# STM32F0xx register map
File version: 1.0
Registers are 32-bit, read-write, reset 0x0 unless marked. A register's access mark holds for its fields unless they carry their own. Offsets are from the block's base; [hi:lo] are bit positions; {n}, {i} and the like mark numbered series; 'fields as' and 'values as' point back to an identical list.

## GPIOF — General-purpose I/Os
Base 0x48001400
Same registers: GPIOB 0x48000400, GPIOC 0x48000800, GPIOD 0x48000C00, GPIOE 0x48001000
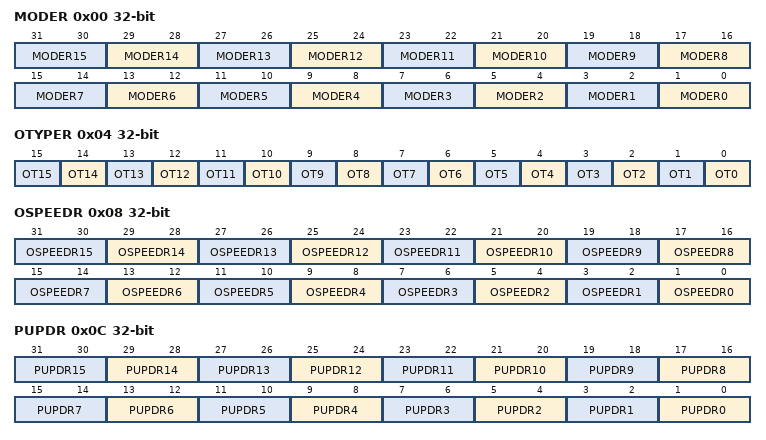
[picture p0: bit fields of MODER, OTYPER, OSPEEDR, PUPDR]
0x00 MODER — GPIO port mode register
  [all] fields
    0=Input mode (Reset); 1=output (General purpose output mode.); 2=Alternate function mode; 3=Analog mode 
  [2n+1:2n] MODER{n} (n=0..15) — Port x configuration bits (y = 0..15)
0x04 OTYPER — GPIO port output type register
  [all] fields
    0=push_pull (Output push-pull (reset state).); 1=open_drain (Output open-drain.)
  [n] OT{n} (n=0..15) — Port x configuration bit {n}
0x08 OSPEEDR — GPIO port output speed register
  [all] fields
    0=low_speed; 1=medium_speed; 2=low_speed_1; 3=high_speed
  [2n+1:2n] OSPEEDR{n} (n=0..15) — Port x configuration bits (y = 0..15)
0x0C PUPDR — GPIO port pull-up/pull-down register
  [all] fields
    0=floating (No Pull-up or Pull-Down.); 1=pull_up (Pull down.); 2=pull_down (Pull up.)
  [2n+1:2n] PUPDR{n} (n=0..15) — Port x configuration bits (y = 0..15)
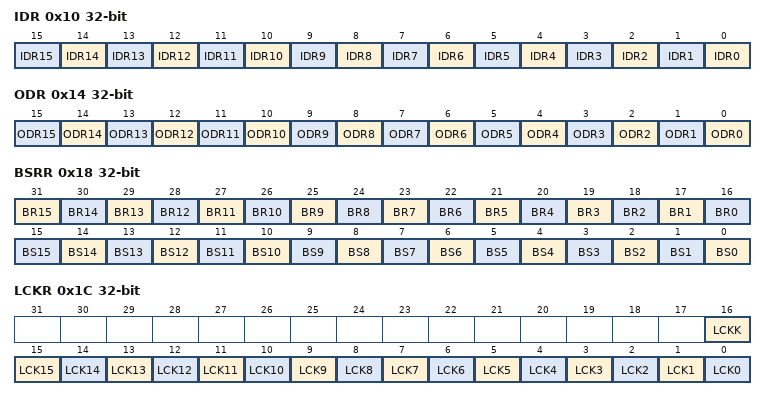
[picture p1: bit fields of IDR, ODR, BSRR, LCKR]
0x10 IDR ro — GPIO port input data register
  [all] fields
    0=Not set flag; 1=set (Set flag.)
  [n] IDR{n} (n=0..15) — Port input data (y = 0..15)
0x14 ODR — GPIO port output data register
  [all] fields
    0=Not set flag; 1=set (Set flag.)
  [n] ODR{n} (n=0..15) — Port output data (y = 0..15)
0x18 BSRR wo — GPIO port bit set/reset register
  [n+16] BR{n} (n=1..15) — Port x reset bit y (y = 0..15)
    0=no_action; 1=Reset action
  [16] BR0 — Port x set bit y (y= 0..15)
    0=no_action; 1=Reset action
  [n] BS{n} (n=0..15) — Port x set bit y (y= 0..15)
    0=no_action; 1=set (Set action.)
0x1C LCKR — GPIO port configuration lock register
  [all] fields
    0=not_locked (Port configuration not locked.); 1=locked (Port configuration locked.)
  [16] LCKK — Port x lock bit y
  [n] LCK{n} (n=0..15) — Port x lock bit y (y= 0..15)
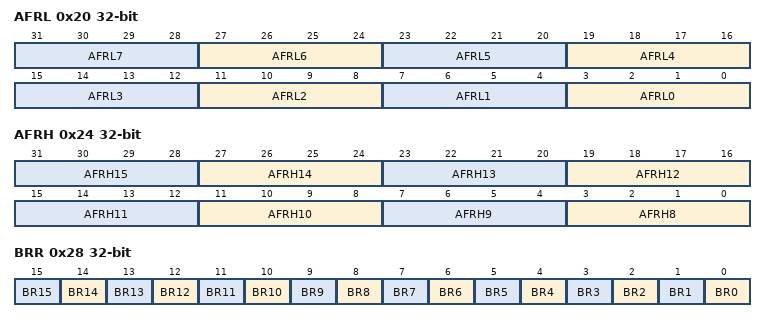
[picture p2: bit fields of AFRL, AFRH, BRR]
0x20 AFRL — GPIO alternate function low register
  [all] fields
    {v}=AF{v} (Select Alternate Function {v}.) (v=0..7)
  [4n+3:4n] AFRL{n} (n=0..7) — Alternate function selection for port x bit y (y = 0..7)
0x24 AFRH — GPIO alternate function high register
  [all] fields
    {v}=AF{v} (Select Alternate Function {v}.) (v=0..7)
  [4n-29:4n-32] AFRH{n} (n=8..15) — Alternate function selection for port x bit y (y = 8..15)
0x28 BRR wo — Port bit reset register
  [all] fields
    0=no_action; 1=Reset action
  [n] BR{n} (n=0..15) — Port x Reset bit y

## GPIOA — General-purpose I/Os
Base 0x48000000
Registers as GPIOF; these are added or differ:
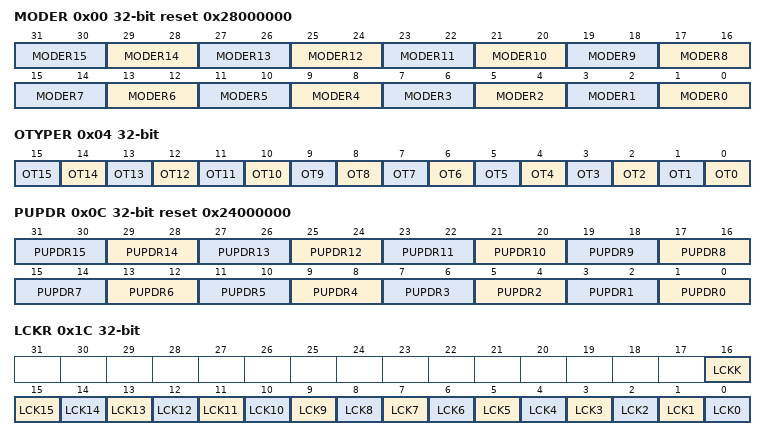
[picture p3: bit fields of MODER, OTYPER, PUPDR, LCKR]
0x00 MODER reset 0x28000000 — GPIO port mode register
  [all] fields
    0=Input mode (Reset); 1=output (General purpose output mode.); 2=Alternate function mode; 3=Analog mode 
  [2n+1:2n] MODER{n} (n=0..15) — Port x configuration bits (y = 0..15)
0x04 OTYPER — GPIO port output type register
  [all] fields
    0=push_pull (Output push-pull (reset state).); 1=open_drain (Output open-drain.)
  [n] OT{n} (n=0..15) — Port x configuration bits (y = 0..15)
0x0C PUPDR reset 0x24000000 — GPIO port pull-up/pull-down register
  [all] fields
    0=floating (No Pull-up or Pull-Down.); 1=pull_up (Pull down.); 2=pull_down (Pull up.)
  [2n+1:2n] PUPDR{n} (n=0..15) — Port x configuration bits (y = 0..15)
0x1C LCKR — GPIO port configuration lock register
  [all] fields
    0=not_locked (Port configuration not locked.); 1=locked (Port configuration locked.)
  [16] LCKK — Port x lock bit y (y= 0..15)
  [n] LCK{n} (n=0..15) — Port x lock bit y (y= 0..15)

## SPI1 — Serial peripheral interface
Base 0x40013000
Same registers: SPI2 0x40003800
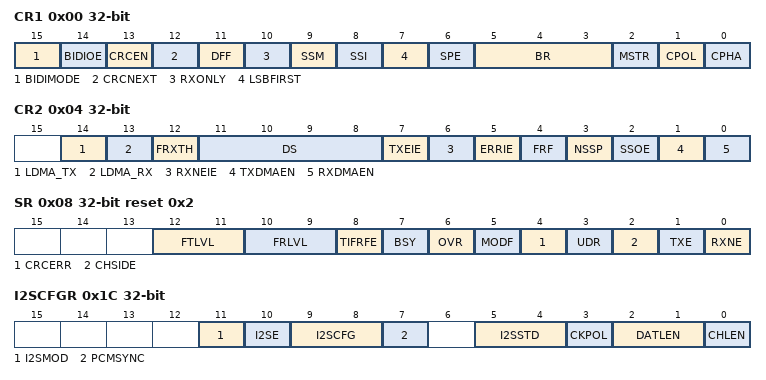
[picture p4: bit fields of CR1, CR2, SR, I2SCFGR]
0x00 CR1 — control register 1
  [15] BIDIMODE — Bidirectional data mode enable
  [14] BIDIOE — Output enable in bidirectional mode
  [13] CRCEN — Hardware CRC calculation enable
    0=disabled (Disable the Rising trigger.); 1=enabled (Enable the Rising trigger.)
  [12] CRCNEXT — CRC transfer next
  [11] DFF — Data frame format
  [10] RXONLY — Receive only
  [9] SSM — Software slave management
  [8] SSI — Internal slave select
  [7] LSBFIRST — Frame format
  [6] SPE — SPI enable
  [5:3] BR — Baud rate control
  [2] MSTR — Master selection
  [1] CPOL — Clock polarity
  [0] CPHA — Clock phase
0x04 CR2 — control register 2
  [14] LDMA_TX — Last DMA transfer for transmission
  [13] LDMA_RX — Last DMA transfer for reception
  [12] FRXTH — FIFO reception threshold
  [11:8] DS — Data size
  [7] TXEIE — Tx buffer empty interrupt enable
  [6] RXNEIE — RX buffer not empty interrupt enable
  [5] ERRIE — Error interrupt enable
  [4] FRF — Frame format
  [3] NSSP — NSS pulse management
  [2] SSOE — SS output enable
  [1] TXDMAEN — Tx buffer DMA enable
    values as CR1.CRCEN
  [0] RXDMAEN — Rx buffer DMA enable
    values as CR1.CRCEN
0x08 SR access per field reset 0x2 — status register
  [12:11] FTLVL ro — FIFO transmission level
  [10:9] FRLVL ro — FIFO reception level
  [8] TIFRFE ro — TI frame format error
  [7] BSY ro — Busy flag
  [6] OVR ro — Overrun flag
  [5] MODF ro — Mode fault
  [4] CRCERR rw — CRC error flag
  [3] UDR ro — Underrun flag
  [2] CHSIDE ro — Channel side
  [1] TXE ro — Transmit buffer empty
  [0] RXNE ro — Receive buffer not empty
0x0C DR — data register
  [15:0] DR — Data register
0x10 CRCPR reset 0x7 — CRC polynomial register
  [15:0] CRCPOLY
0x14 RXCRCR ro — RX CRC register
  [15:0] RxCRC
0x18 TXCRCR ro — TX CRC register
  [15:0] TxCRC
0x1C I2SCFGR — I2S configuration register
  [11] I2SMOD — I2S mode selection
  [10] I2SE — I2S Enable
  [9:8] I2SCFG — I2S configuration mode
  [7] PCMSYNC — PCM frame synchronization
  [5:4] I2SSTD — I2S standard selection
  [3] CKPOL — Steady state clock polarity
  [2:1] DATLEN — Data length to be transferred
  [0] CHLEN — Channel length (number of bits per audio channel)
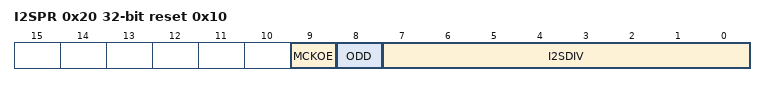
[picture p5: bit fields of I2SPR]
0x20 I2SPR reset 0x10 — I2S prescaler register
  [9] MCKOE — Master clock output enable
  [8] ODD — Odd factor for the prescaler
  [7:0] I2SDIV — I2S Linear prescaler
